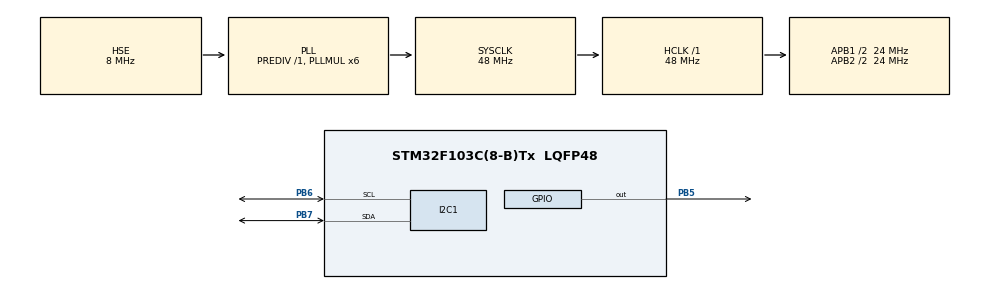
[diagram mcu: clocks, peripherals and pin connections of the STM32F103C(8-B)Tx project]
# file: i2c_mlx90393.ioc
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I2C1.I2C_Mode=I2C_Standard
Mcu.Family=STM32F1
Mcu.Name=STM32F103C(8-B)Tx
Mcu.Package=LQFP48
NVIC.I2C1_EV_IRQn=true\:0\:0\:false\:false\:true\:true\:true\:true
NVIC.PriorityGroup=NVIC_PRIORITYGROUP_4
NVIC.TIM4_IRQn=true\:0\:0\:false\:false\:true\:true\:true\:true
PA13.Mode=Serial_Wire
PA13.Signal=SYS_JTMS-SWDIO
PA14.Mode=Serial_Wire
PA14.Signal=SYS_JTCK-SWCLK
PB5.Signal=GPIO_Output
PB6.Mode=I2C
PB6.Signal=I2C1_SCL
PB7.Mode=I2C
PB7.Signal=I2C1_SDA
PD0-OSC_IN.Mode=HSE-External-Oscillator
PD0-OSC_IN.Signal=RCC_OSC_IN
PD1-OSC_OUT.Mode=HSE-External-Oscillator
PD1-OSC_OUT.Signal=RCC_OSC_OUT
ProjectManager.HeapSize=0x200
ProjectManager.StackSize=0x400
ProjectManager.TargetToolchain=STM32CubeIDE
RCC.AHBFreq_Value=48000000
RCC.APB1CLKDivider=RCC_HCLK_DIV2
RCC.APB1Freq_Value=24000000
RCC.APB1TimFreq_Value=48000000
RCC.APB2CLKDivider=RCC_HCLK_DIV2
RCC.APB2Freq_Value=24000000
RCC.APB2TimFreq_Value=48000000
RCC.EnbaleCSS=true
RCC.HCLKFreq_Value=48000000
RCC.PLLMUL=RCC_PLL_MUL6
RCC.PLLSourceVirtual=RCC_PLLSOURCE_HSE
RCC.SYSCLKFreq_VALUE=48000000
RCC.SYSCLKSource=RCC_SYSCLKSOURCE_PLLCLK
RCC.USBFreq_Value=48000000
TIM4.Period=2500-1
TIM4.Prescaler=480-1
VP_TIM4_VS_ClockSourceINT.Mode=Internal
board=custom

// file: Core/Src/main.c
/* USER CODE BEGIN Header */
/**
 ******************************************************************************
 * @file           : main.c
 * @brief          : Main program body
 ******************************************************************************
 * @attention
 *
 * Copyright (c) 2023 STMicroelectronics.
 * All rights reserved.
 *
 * This software is licensed under terms that can be found in the LICENSE file
 * in the root directory of this software component.
 * If no LICENSE file comes with this software, it is provided AS-IS.
 *
 ******************************************************************************
 */
/* USER CODE END Header */
#include "main.h"

/* USER CODE BEGIN Includes */
#include "math.h"
#include "i2c_er.h"
#include "mlx90393.h"
/* USER CODE END Includes */

/* USER CODE BEGIN PD */
#define MLX90393_Address 12 << 1
/* USER CODE END PD */

I2C_HandleTypeDef hi2c1;

TIM_HandleTypeDef htim4;

/* USER CODE BEGIN PV */
HAL_StatusTypeDef state = HAL_OK; // Результат выполнения запроса

// Флаг готовности выполнить вычисления, 1 раз в 40 мс
volatile uint8_t isCalculation = 0;

// Данные успешно прочитаны
uint8_t isDataReady = 0;

// Команды для одиночного измерения и чтения данных
uint8_t comSM = 0x3E, comRM = 0x4E;

uint8_t pRxData[7] = { 0 };

// Вычисленный результат
int16_t resX;
int16_t resY;
int16_t resZ;

// Смещение которое будем вычитать из результата
int16_t xOffset;
int16_t yOffset;
int16_t zOffset;

/* USER CODE END PV */

void SystemClock_Config(void);
static void MX_GPIO_Init(void);
static void MX_I2C1_Init(void);
static void MX_TIM4_Init(void);
/* USER CODE BEGIN PFP */
uint8_t MLX90393_Get_Data(void);
uint8_t MLX90393_Calibrate(void);
/* USER CODE END PFP */

int main(void)
{

  /* MCU Configuration--------------------------------------------------------*/

  /* Reset of all peripherals, Initializes the Flash interface and the Systick. */
  HAL_Init();

  /* Configure the system clock */
  SystemClock_Config();

  /* USER CODE BEGIN SysInit */
  __HAL_RCC_I2C1_CLK_ENABLE();
  HAL_Delay(100);
  __HAL_RCC_I2C1_FORCE_RESET();
  HAL_Delay(100);
  __HAL_RCC_I2C1_RELEASE_RESET();
  HAL_Delay(100);
  /* USER CODE END SysInit */

  /* Initialize all configured peripherals */
  MX_GPIO_Init();
  MX_I2C1_Init();
  MX_TIM4_Init();
  /* USER CODE BEGIN 2 */
  // MLX90393 включается от ножки PB5
  HAL_GPIO_WritePin(GPIOB, GPIO_PIN_5, GPIO_PIN_SET);
  HAL_Delay(500);

  // Проверяем готовность I2C и MLX90393
  state = HAL_I2C_IsDeviceReady(&hi2c1, (uint16_t) MLX90393_Address, 1, HAL_MAX_DELAY);
  if (state == HAL_BUSY) {
    // При данном флаге вызываем функцию переинициализации I2C1
    I2C_ClearBusyFlagErratum(&hi2c1, 1000);
  }

  // Производим сброс MLX90393
  state = init_MLX90393(&hi2c1, (uint16_t) MLX90393_Address);
  if (state != HAL_OK) {
    // Если при инициализации произошла ошибка, перезапускаем микроконтроллер и MLX90393
    __set_FAULTMASK(1); // Запрещаем все маскируемые прерывания
    NVIC_SystemReset(); // Программный сброс
  }

  // Калибруем MLX90393
  if (MLX90393_Calibrate()) {
    // Калибровка завершилась с ошибкой, перезапускаем микроконтроллер и MLX90393
    __set_FAULTMASK(1); // Запрещаем все маскируемые прерывания
    NVIC_SystemReset(); // Программный сброс
  }

  // Запускаем опрос MLX90393 каждые 25 мс
  __HAL_TIM_CLEAR_FLAG(&htim4, TIM_SR_UIF); // Очищаем флаг
  HAL_TIM_Base_Start_IT(&htim4);

  /* USER CODE END 2 */

  /* Infinite loop */
  /* USER CODE BEGIN WHILE */
  while (1) {
    if (isCalculation) {
      isCalculation = 0;
      // Получаем данные и отправляем запрос на получение данных каждые 40 мс
      // В случае ошибки переходим на следующую итерацию цикла
      if (MLX90393_Get_Data()) continue;
      //MLX90393_Get_Data();
    }

    if (isDataReady) {
      isDataReady = 0;
      // Проверяем по байту статуса, количество пришедших данных, обрабатываем если равно 0x02
      // (всего байт 2 * 0x02 + 2) равно 6 байт
      if ((pRxData[0] & 0x03) == 0x02) {

        resX = (((int16_t) pRxData[1] << 8 | pRxData[2]) - xOffset);
        resY = (((int16_t) pRxData[3] << 8 | pRxData[4]) - yOffset);
        resZ = (((int16_t) pRxData[5] << 8 | pRxData[6]) - zOffset);
      }
    }
    /* USER CODE END WHILE */

  }
}

void SystemClock_Config(void)
{
  RCC_OscInitTypeDef RCC_OscInitStruct = {0};
  RCC_ClkInitTypeDef RCC_ClkInitStruct = {0};

  /** Initializes the RCC Oscillators according to the specified parameters
  * in the RCC_OscInitTypeDef structure.
  */
  RCC_OscInitStruct.OscillatorType = RCC_OSCILLATORTYPE_HSE;
  RCC_OscInitStruct.HSEState = RCC_HSE_ON;
  RCC_OscInitStruct.HSEPredivValue = RCC_HSE_PREDIV_DIV1;
  RCC_OscInitStruct.HSIState = RCC_HSI_ON;
  RCC_OscInitStruct.PLL.PLLState = RCC_PLL_ON;
  RCC_OscInitStruct.PLL.PLLSource = RCC_PLLSOURCE_HSE;
  RCC_OscInitStruct.PLL.PLLMUL = RCC_PLL_MUL6;
  if (HAL_RCC_OscConfig(&RCC_OscInitStruct) != HAL_OK)
  {
    Error_Handler();
  }

  /** Initializes the CPU, AHB and APB buses clocks
  */
  RCC_ClkInitStruct.ClockType = RCC_CLOCKTYPE_HCLK|RCC_CLOCKTYPE_SYSCLK
                              |RCC_CLOCKTYPE_PCLK1|RCC_CLOCKTYPE_PCLK2;
  RCC_ClkInitStruct.SYSCLKSource = RCC_SYSCLKSOURCE_PLLCLK;
  RCC_ClkInitStruct.AHBCLKDivider = RCC_SYSCLK_DIV1;
  RCC_ClkInitStruct.APB1CLKDivider = RCC_HCLK_DIV2;
  RCC_ClkInitStruct.APB2CLKDivider = RCC_HCLK_DIV2;

  if (HAL_RCC_ClockConfig(&RCC_ClkInitStruct, FLASH_LATENCY_1) != HAL_OK)
  {
    Error_Handler();
  }

  /** Enables the Clock Security System
  */
  HAL_RCC_EnableCSS();
}

static void MX_I2C1_Init(void)
{

  hi2c1.Instance = I2C1;
  hi2c1.Init.ClockSpeed = 100000;
  hi2c1.Init.DutyCycle = I2C_DUTYCYCLE_2;
  hi2c1.Init.OwnAddress1 = 0;
  hi2c1.Init.AddressingMode = I2C_ADDRESSINGMODE_7BIT;
  hi2c1.Init.DualAddressMode = I2C_DUALADDRESS_DISABLE;
  hi2c1.Init.OwnAddress2 = 0;
  hi2c1.Init.GeneralCallMode = I2C_GENERALCALL_DISABLE;
  hi2c1.Init.NoStretchMode = I2C_NOSTRETCH_DISABLE;
  if (HAL_I2C_Init(&hi2c1) != HAL_OK)
  {
    Error_Handler();
  }

}

static void MX_TIM4_Init(void)
{

  TIM_ClockConfigTypeDef sClockSourceConfig = {0};
  TIM_MasterConfigTypeDef sMasterConfig = {0};

  htim4.Instance = TIM4;
  htim4.Init.Prescaler = 480-1;
  htim4.Init.CounterMode = TIM_COUNTERMODE_UP;
  htim4.Init.Period = 4000-1;
  htim4.Init.ClockDivision = TIM_CLOCKDIVISION_DIV1;
  htim4.Init.AutoReloadPreload = TIM_AUTORELOAD_PRELOAD_DISABLE;
  if (HAL_TIM_Base_Init(&htim4) != HAL_OK)
  {
    Error_Handler();
  }
  sClockSourceConfig.ClockSource = TIM_CLOCKSOURCE_INTERNAL;
  if (HAL_TIM_ConfigClockSource(&htim4, &sClockSourceConfig) != HAL_OK)
  {
    Error_Handler();
  }
  sMasterConfig.MasterOutputTrigger = TIM_TRGO_RESET;
  sMasterConfig.MasterSlaveMode = TIM_MASTERSLAVEMODE_DISABLE;
  if (HAL_TIMEx_MasterConfigSynchronization(&htim4, &sMasterConfig) != HAL_OK)
  {
    Error_Handler();
  }

}

static void MX_GPIO_Init(void)
{
  GPIO_InitTypeDef GPIO_InitStruct = {0};

  /* GPIO Ports Clock Enable */
  __HAL_RCC_GPIOD_CLK_ENABLE();
  __HAL_RCC_GPIOA_CLK_ENABLE();
  __HAL_RCC_GPIOB_CLK_ENABLE();

  /*Configure GPIO pin Output Level */
  HAL_GPIO_WritePin(GPIOB, GPIO_PIN_5, GPIO_PIN_RESET);

  /*Configure GPIO pin : PB5 */
  GPIO_InitStruct.Pin = GPIO_PIN_5;
  GPIO_InitStruct.Mode = GPIO_MODE_OUTPUT_PP;
  GPIO_InitStruct.Pull = GPIO_NOPULL;
  GPIO_InitStruct.Speed = GPIO_SPEED_FREQ_LOW;
  HAL_GPIO_Init(GPIOB, &GPIO_InitStruct);

/* USER CODE BEGIN MX_GPIO_Init_2 */
/*
  // Код для сброса линии USB
  // Инициализируем пин DP как выход
  GPIO_InitStruct.Pin = GPIO_PIN_12;
  GPIO_InitStruct.Mode = GPIO_MODE_OUTPUT_PP;
  GPIO_InitStruct.Speed = GPIO_SPEED_FREQ_LOW;
  HAL_GPIO_Init(GPIOA, &GPIO_InitStruct);
  HAL_GPIO_WritePin(GPIOA, GPIO_PIN_12, GPIO_PIN_RESET); // Прижимаем DP к "земле"
  for (uint16_t i = 0; i < 1000; i++) {
  }; // Немного ждём

  // Переинициализируем пин для работы с USB
  GPIO_InitStruct.Mode = GPIO_MODE_INPUT;
  GPIO_InitStruct.Pull = GPIO_NOPULL;
  HAL_GPIO_Init(GPIOA, &GPIO_InitStruct);
  for (uint16_t i = 0; i < 1000; i++) {
  }; // Немного ждём
*/
/* USER CODE END MX_GPIO_Init_2 */
}

/* USER CODE BEGIN 4 */

void HAL_TIM_PeriodElapsedCallback(TIM_HandleTypeDef *htim) {
  if (htim->Instance == TIM4) {
    isCalculation = 1;
  }
}

/**
 * В случае ошибки возвращаем 1
 */
uint8_t MLX90393_Get_Data(void) {
  // Выполняем запрос на считывание данных
  state = HAL_I2C_Master_Transmit(&hi2c1, (uint16_t) MLX90393_Address, (uint8_t*) &comRM, 1, HAL_MAX_DELAY);
  if (state != HAL_OK) return 1;
  state = HAL_I2C_Master_Receive(&hi2c1, (uint16_t) MLX90393_Address, pRxData, 7, HAL_MAX_DELAY);
  if (state != HAL_OK) return 1;

  // Запускаем новое измерение
  state = HAL_I2C_Master_Transmit(&hi2c1, (uint16_t) MLX90393_Address, (uint8_t*) &comSM, 1, HAL_MAX_DELAY);
  if (state != HAL_OK) return 1;
  state = HAL_I2C_Master_Receive(&hi2c1, (uint16_t) MLX90393_Address, pRxData, 1, HAL_MAX_DELAY);
  if (state != HAL_OK) return 1;

  // Ошибок нет, устанавливаем флаг о готовности данных
  isDataReady = 1;

  return 0;
}

/**
 * В случае ошибки возвращаем 1
 */
uint8_t MLX90393_Calibrate(void) {
  int32_t xCal = 0;
  int32_t yCal = 0;
  int32_t zCal = 0;
  // Считаем сколько реально было выполнено итераций по получению данных
  uint16_t count = 0;

  // Запускаем новое измерение
  state = HAL_I2C_Master_Transmit(&hi2c1, (uint16_t) MLX90393_Address, (uint8_t*) &comSM, 1, HAL_MAX_DELAY);
  if (state != HAL_OK) return 1;
  state = HAL_I2C_Master_Receive(&hi2c1, (uint16_t) MLX90393_Address, pRxData, 1, HAL_MAX_DELAY);
  if (state != HAL_OK) return 1;

  // Калибровку выполняем за 2,5 секунды, 100 итераций * 25 мс
  for (uint16_t i = 0; i < 100; i++) {
    HAL_Delay(25);
    // Если произошла ошибка при получении данных, переходим на следующую итерацию
    if (MLX90393_Get_Data()) continue;

    if (isDataReady) {
      isDataReady = 0;
      count++;
      xCal += (int16_t) pRxData[1] << 8 | pRxData[2];
      yCal += (int16_t) pRxData[3] << 8 | pRxData[4];
      zCal += (int16_t) pRxData[5] << 8 | pRxData[6];
    }
  }
  xOffset = (int16_t) (xCal / count);
  yOffset = (int16_t) (yCal / count);
  zOffset = (int16_t) (zCal / count);

  // Функция завершилась без ошибок
  return 0;
}
/* USER CODE END 4 */

void Error_Handler(void)
{
  __disable_irq();
  while (1) {
  }
}
